# cc13x2_cc26x2 register map
File version: 2.1
CPU: CM4 r0p1, little endian, MPU, FPU, 3 interrupt priority bits
Registers are 32-bit, read-write, reset 0x0 unless marked. A register's access mark holds for its fields unless they carry their own. Offsets are from the block's base; [hi:lo] are bit positions; {n}, {i} and the like mark numbered series.

## CPU_FPB — Cortex-M's Flash Patch and Breakpoint (FPB)
Base 0xE0002000
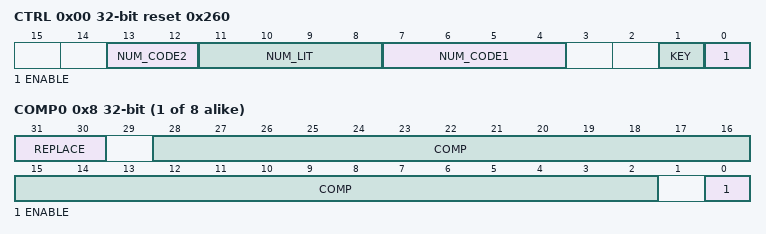
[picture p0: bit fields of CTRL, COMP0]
0x00 CTRL reset 0x260 — Control his register is used to enable the flash patch block.
  [13:12] NUM_CODE2, [11:8] NUM_LIT, [7:4] NUM_CODE1, [1] KEY, [0] ENABLE
0x04 REMAP reset 0x20000000 — Remap his register provides the remap base address location where a matched addresses are remapped. The three most significant bits and the five least significant bits of the remap base address are hard-coded to 3'b001 and 5'b00000 respectively. The remap base address must be in system space and is it required to be 8-word aligned, with one word allocated to each of the eight FPB comparators.
  [28:5] REMAP
{0x8+4i} COMP{i} (i=0..7) — Comparator {i}
  [31:30] REPLACE, [28:2] COMP, [0] ENABLE

## CPU_ITM — Cortex-M's Instrumentation Trace Macrocell (ITM)
Base 0xE0000000
{0x0+4i} STIM{i} (i=0..31) — Stimulus Port {i}
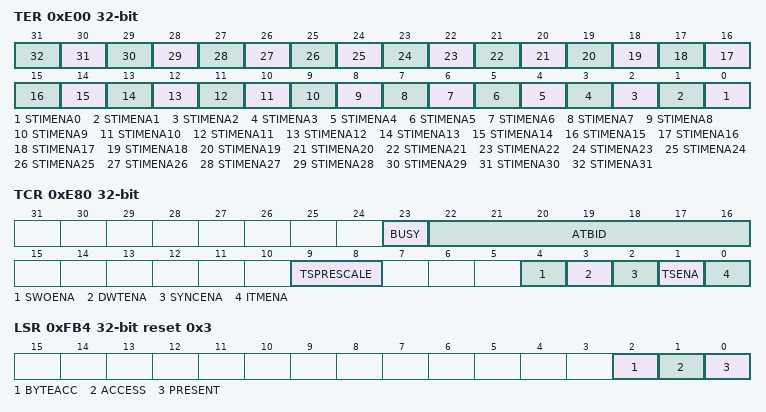
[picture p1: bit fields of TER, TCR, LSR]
0xE00 TER — Trace Enable se the Trace Enable Register to generate trace data by writing to the corresponding stimulus port. Note: Privileged writes are accepted to this register if TCR.ITMENA is set. User writes are accepted to this register if TCR.ITMENA is set and the appropriate privilege mask is cleared. Privileged access to the stimulus ports enables an RTOS kernel to guarantee instrumentation slots or bandwidth as required.
  [n] STIMENA{n} (n=0..31)
0xE40 TPR — Trace Privilege his register is used to enable an operating system to control which stimulus ports are accessible by user code. This register can only be used in privileged mode.
  [3:0] PRIVMASK
0xE80 TCR — Trace Control se this register to configure and control ITM transfers. This register can only be written in privilege mode. DWT is not enabled in the ITM block. However, DWT stimulus entry into the FIFO is controlled by DWTENA. If DWT requires timestamping, the TSENA bit must be set.
  [23] BUSY, [22:16] ATBID, [9:8] TSPRESCALE, [4] SWOENA, [3] DWTENA, [2] SYNCENA, [1] TSENA, [0] ITMENA
0xFB0 LAR wo — Lock Access his register is used to prevent write accesses to the Control Registers: TER, TPR and TCR.
  [31:0] LOCK_ACCESS
0xFB4 LSR ro reset 0x3 — Lock Status se this register to enable write accesses to the Control Register.
  [2] BYTEACC, [1] ACCESS, [0] PRESENT

## CPU_ROM_TABLE — Cortex-M's ROM table
Base 0xE00FF000
0x00 SCS ro reset 0xFFF0F003 — System Control Space Component
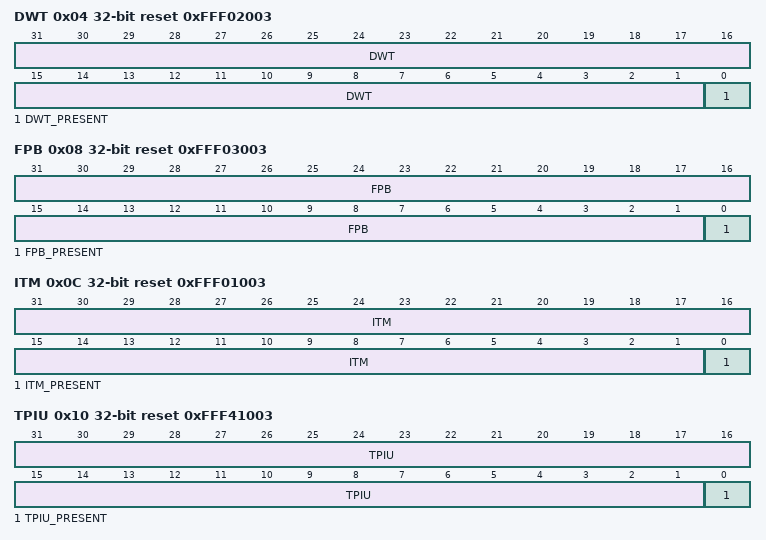
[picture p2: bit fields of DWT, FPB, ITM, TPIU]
0x04 DWT ro reset 0xFFF02003 — Data Watchpoint and Trace Component oints to the Data Watchpoint and Trace block at 0xE0001000. Value has bit [0] set if DWT is present.
  [31:1] DWT, [0] DWT_PRESENT
0x08 FPB ro reset 0xFFF03003 — Flash Patch and Breakpoint Component oints to the Flash Patch and Breakpoint block at 0xE0002000. Value has bit [0] set to 1 if FPB is present.
  [31:1] FPB, [0] FPB_PRESENT
0x0C ITM ro reset 0xFFF01003 — Instrumentation Trace Component oints to the Instrumentation Trace block at 0xE0000000. Value has bit [0] set if ITM is present.
  [31:1] ITM, [0] ITM_PRESENT
0x10 TPIU ro reset 0xFFF41003 — Trace Port Interface Component oints to the TPIU. Value has bit [0] set to 1 if TPIU is present. TPIU is at 0xE0040000.
  [31:1] TPIU, [0] TPIU_PRESENT
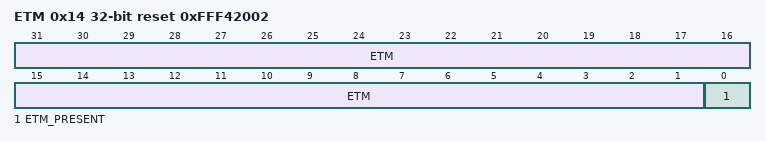
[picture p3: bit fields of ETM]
0x14 ETM ro reset 0xFFF42002 — Enhanced Trace Component oints to the ETM. Value has bit [0] set to 1 if ETM is present. ETM is at 0xE0041000.
  [31:1] ETM, [0] ETM_PRESENT
0x18 END ro — End Marker arks the end of the ROM table. If CoreSight components are added, they are added starting from this location and the End marker is moved to the next location after the additional components.
0xFCC SYSTEM_ACCESS ro reset 0x1 — System Memory Map Access for DAP
  [0] SYSTEM_ACCESS
